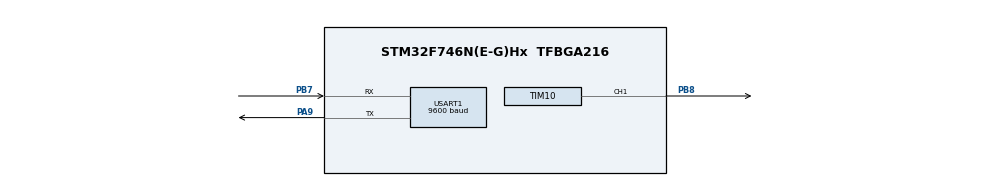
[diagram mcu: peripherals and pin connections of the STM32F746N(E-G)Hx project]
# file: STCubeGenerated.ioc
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Mcu.Family=STM32F7
Mcu.Name=STM32F746N(E-G)Hx
Mcu.Package=TFBGA216
NVIC.PriorityGroup=NVIC_PRIORITYGROUP_4
NVIC.TIM1_UP_TIM10_IRQn=true\:0\:0\:false\:false\:true
PA9.Mode=Asynchronous
PA9.Signal=USART1_TX
PB7.Mode=Asynchronous
PB7.Signal=USART1_RX
PB8.Signal=S_TIM10_CH1
ProjectManager.HeapSize=0x200
ProjectManager.StackSize=0x400
ProjectManager.TargetToolchain=MDK-ARM V5
RCC.HSE_VALUE=25000000
RCC.HSI_VALUE=16000000
RCC.LSE_VALUE=32768
RCC.USBFreq_Value=96000000
RCC.VCOOutputFreq_Value=192000000
SH.S_TIM10_CH1.0=TIM10_CH1,Forced Output1 CH1
TIM10.Prescaler=1024
USART1.BaudRate=9600
USART1.WordLength=UART_WORDLENGTH_8B
VP_TIM10_VS_ClockSourceINT.Mode=Enable_Timer
board=STCubeGenerated

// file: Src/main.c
/**
  ******************************************************************************
  * File Name          : main.c
  * Description        : Main program body
  ******************************************************************************
  *
  * COPYRIGHT(c) 2017 STMicroelectronics
  *
  * Redistribution and use in source and binary forms, with or without modification,
  * are permitted provided that the following conditions are met:
  *   1. Redistributions of source code must retain the above copyright notice,
  *      this list of conditions and the following disclaimer.
  *   2. Redistributions in binary form must reproduce the above copyright notice,
  *      this list of conditions and the following disclaimer in the documentation
  *      and/or other materials provided with the distribution.
  *   3. Neither the name of STMicroelectronics nor the names of its contributors
  *      may be used to endorse or promote products derived from this software
  *      without specific prior written permission.
  *
  * THIS SOFTWARE IS PROVIDED BY THE COPYRIGHT HOLDERS AND CONTRIBUTORS "AS IS"
  * AND ANY EXPRESS OR IMPLIED WARRANTIES, INCLUDING, BUT NOT LIMITED TO, THE
  * IMPLIED WARRANTIES OF MERCHANTABILITY AND FITNESS FOR A PARTICULAR PURPOSE ARE
  * DISCLAIMED. IN NO EVENT SHALL THE COPYRIGHT HOLDER OR CONTRIBUTORS BE LIABLE
  * FOR ANY DIRECT, INDIRECT, INCIDENTAL, SPECIAL, EXEMPLARY, OR CONSEQUENTIAL
  * DAMAGES (INCLUDING, BUT NOT LIMITED TO, PROCUREMENT OF SUBSTITUTE GOODS OR
  * SERVICES; LOSS OF USE, DATA, OR PROFITS; OR BUSINESS INTERRUPTION) HOWEVER
  * CAUSED AND ON ANY THEORY OF LIABILITY, WHETHER IN CONTRACT, STRICT LIABILITY,
  * OR TORT (INCLUDING NEGLIGENCE OR OTHERWISE) ARISING IN ANY WAY OUT OF THE USE
  * OF THIS SOFTWARE, EVEN IF ADVISED OF THE POSSIBILITY OF SUCH DAMAGE.
  *
  ******************************************************************************
  */
#include "main.h"
#include "stm32f7xx_hal.h"

TIM_HandleTypeDef htim10;

UART_HandleTypeDef huart1;

/* USER CODE BEGIN PV */
/* Private variables ---------------------------------------------------------*/
#ifdef __GNUC__/*Enables putchar and getchar functionality*/
	#define PUTCHAR_PROTOTYPE int __io_putchar(int ch)
	#define GETCHAR_PROTOTYPE int __io_getchar()
#else
	#define PUTCHAR_PROTOTYPE int fputc(int ch, FILE *f)
	#define GETCHAR_PROTOTYPE int fgetc(FILE *f)
#endif /*__GNUC__*/

/* USER CODE END PV */

void SystemClock_Config(void);
void Error_Handler(void);
static void MX_GPIO_Init(void);
static void MX_USART1_UART_Init(void);
static void MX_TIM10_Init(void);

void HAL_TIM_MspPostInit(TIM_HandleTypeDef *htim);

/* USER CODE BEGIN PFP */
/* Private function prototypes -----------------------------------------------*/
PUTCHAR_PROTOTYPE{/*So that putchar can be done through UART and terminal*/
	HAL_UART_Transmit(&huart1, (uint8_t *)&ch, 1, 0xFFFF);
	return ch;
}
GETCHAR_PROTOTYPE{/*so that getchar can be done through UART and terminal*/
	char ch;
	HAL_UART_Receive(&huart1,(uint8_t *)&ch,1,0xFFFF);
	return ch;
}

/* USER CODE END PFP */

int main(void)
{

  /* USER CODE BEGIN 1 */
	char String[MAX_LENGTH];
  /* USER CODE END 1 */

  /* MCU Configuration----------------------------------------------------------*/

  /* Reset of all peripherals, Initializes the Flash interface and the Systick. */
  HAL_Init();

  /* Configure the system clock */
  SystemClock_Config();

  /* Initialize all configured peripherals */
  MX_GPIO_Init();
  MX_USART1_UART_Init();
  MX_TIM10_Init();

  /* USER CODE BEGIN 2 */
	printf("Hello World!\n\r");
  /* USER CODE END 2 */

  /* Infinite loop */
  while (1)
  {

  }

}

/** System Clock Configuration
*/
void SystemClock_Config(void)
{

  RCC_OscInitTypeDef RCC_OscInitStruct;
  RCC_ClkInitTypeDef RCC_ClkInitStruct;
  RCC_PeriphCLKInitTypeDef PeriphClkInitStruct;

    /**Configure the main internal regulator output voltage
    */
  __HAL_RCC_PWR_CLK_ENABLE();

  __HAL_PWR_VOLTAGESCALING_CONFIG(PWR_REGULATOR_VOLTAGE_SCALE3);

    /**Initializes the CPU, AHB and APB busses clocks
    */
  RCC_OscInitStruct.OscillatorType = RCC_OSCILLATORTYPE_HSI;
  RCC_OscInitStruct.HSIState = RCC_HSI_ON;
  RCC_OscInitStruct.HSICalibrationValue = 16;
  RCC_OscInitStruct.PLL.PLLState = RCC_PLL_NONE;
  if (HAL_RCC_OscConfig(&RCC_OscInitStruct) != HAL_OK)
  {
    Error_Handler();
  }

    /**Initializes the CPU, AHB and APB busses clocks
    */
  RCC_ClkInitStruct.ClockType = RCC_CLOCKTYPE_HCLK|RCC_CLOCKTYPE_SYSCLK
                              |RCC_CLOCKTYPE_PCLK1|RCC_CLOCKTYPE_PCLK2;
  RCC_ClkInitStruct.SYSCLKSource = RCC_SYSCLKSOURCE_HSI;
  RCC_ClkInitStruct.AHBCLKDivider = RCC_SYSCLK_DIV1;
  RCC_ClkInitStruct.APB1CLKDivider = RCC_HCLK_DIV1;
  RCC_ClkInitStruct.APB2CLKDivider = RCC_HCLK_DIV1;

  if (HAL_RCC_ClockConfig(&RCC_ClkInitStruct, FLASH_LATENCY_0) != HAL_OK)
  {
    Error_Handler();
  }

  PeriphClkInitStruct.PeriphClockSelection = RCC_PERIPHCLK_USART1;
  PeriphClkInitStruct.Usart1ClockSelection = RCC_USART1CLKSOURCE_PCLK2;
  if (HAL_RCCEx_PeriphCLKConfig(&PeriphClkInitStruct) != HAL_OK)
  {
    Error_Handler();
  }

    /**Configure the Systick interrupt time
    */
  HAL_SYSTICK_Config(HAL_RCC_GetHCLKFreq()/1000);

    /**Configure the Systick
    */
  HAL_SYSTICK_CLKSourceConfig(SYSTICK_CLKSOURCE_HCLK);

  /* SysTick_IRQn interrupt configuration */
  HAL_NVIC_SetPriority(SysTick_IRQn, 0, 0);
}

/* TIM10 init function */
static void MX_TIM10_Init(void)
{

  TIM_OC_InitTypeDef sConfigOC;

  htim10.Instance = TIM10;
  htim10.Init.Prescaler = 1024;
  htim10.Init.CounterMode = TIM_COUNTERMODE_UP;
  htim10.Init.Period = 0;
  htim10.Init.ClockDivision = TIM_CLOCKDIVISION_DIV1;
  htim10.Init.AutoReloadPreload = TIM_AUTORELOAD_PRELOAD_DISABLE;
  if (HAL_TIM_Base_Init(&htim10) != HAL_OK)
  {
    Error_Handler();
  }

  if (HAL_TIM_OC_Init(&htim10) != HAL_OK)
  {
    Error_Handler();
  }

  sConfigOC.OCMode = TIM_OCMODE_FORCED_ACTIVE;
  sConfigOC.Pulse = 0;
  sConfigOC.OCPolarity = TIM_OCPOLARITY_HIGH;
  sConfigOC.OCFastMode = TIM_OCFAST_DISABLE;
  if (HAL_TIM_OC_ConfigChannel(&htim10, &sConfigOC, TIM_CHANNEL_1) != HAL_OK)
  {
    Error_Handler();
  }

  HAL_TIM_MspPostInit(&htim10);

}

/* USART1 init function */
static void MX_USART1_UART_Init(void)
{

  huart1.Instance = USART1;
  huart1.Init.BaudRate = 9600;
  huart1.Init.WordLength = UART_WORDLENGTH_8B;
  huart1.Init.StopBits = UART_STOPBITS_1;
  huart1.Init.Parity = UART_PARITY_NONE;
  huart1.Init.Mode = UART_MODE_TX_RX;
  huart1.Init.HwFlowCtl = UART_HWCONTROL_NONE;
  huart1.Init.OverSampling = UART_OVERSAMPLING_16;
  huart1.Init.OneBitSampling = UART_ONE_BIT_SAMPLE_DISABLE;
  huart1.AdvancedInit.AdvFeatureInit = UART_ADVFEATURE_NO_INIT;
  if (HAL_UART_Init(&huart1) != HAL_OK)
  {
    Error_Handler();
  }

}

/** Pinout Configuration
*/
static void MX_GPIO_Init(void)
{

  /* GPIO Ports Clock Enable */
  __HAL_RCC_GPIOB_CLK_ENABLE();
  __HAL_RCC_GPIOA_CLK_ENABLE();

}

void Error_Handler(void)
{
  while(1)
  {
  }
}

/************************ (C) COPYRIGHT STMicroelectronics *****END OF FILE****/
